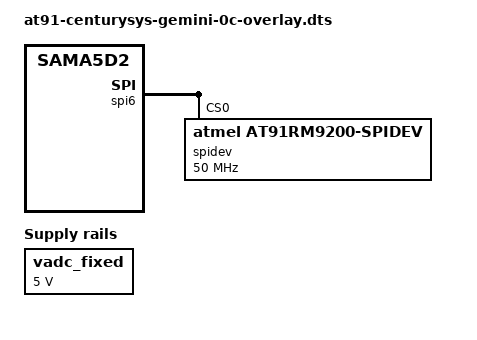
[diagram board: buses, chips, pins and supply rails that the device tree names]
// SPDX-License-Identifier: (GPL-2.0+ OR MIT)
/*
 * at91-centurysys-gemini-0c-overlay.dts - Device Tree Overlay file (xio_id: 0x0c)
 *                                           for Century Systems Gemini board
 *
 *  Copyright (C) 2023 Century Systems
 *                     Takeyoshi Kikuchi <kikuchi@centurysys.co.jp>
 */

/dts-v1/;
/plugin/;
#include "sama5d2-pinfunc.h"
#include <dt-bindings/mfd/atmel-flexcom.h>
#include <dt-bindings/gpio/gpio.h>
#include <dt-bindings/interrupt-controller/irq.h>
#include <dt-bindings/regulator/active-semi,8945a-regulator.h>

/ {
	compatible = "atmel,sama5d2-gemini", "atmel,sama5d2", "atmel,sama5";

	fragment@0 {
		target-path = "/";
		__overlay__ {
			vadc_fixed: fixedregulator_adc {
				compatible = "regulator-fixed";
				regulator-name = "VADC_5V";
				regulator-min-microvolt = <5000000>;
				regulator-max-microvolt = <5000000>;
			};
		};
	};

	fragment@1 {
		target = <&spi6>;
		__overlay__ {
			#address-cells = <1>;
			#size-cells = <0>;

			spidev@0 {
				compatible = "atmel,at91rm9200-spidev";
				reg = <0>;
				spi-max-frequency = <50000000>;
			};
		};
	};
};
